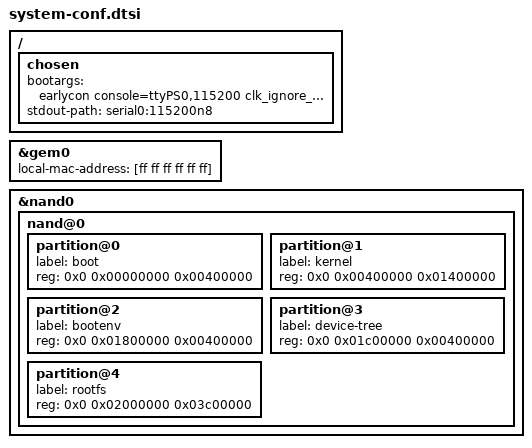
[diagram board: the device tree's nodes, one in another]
/*
 * CAUTION: This file is automatically generated by PetaLinux SDK.
 * DO NOT modify this file
 */


/ {
	chosen {
		bootargs = " earlycon console=ttyPS0,115200 clk_ignore_unused init_fatal_sh=1";
		stdout-path = "serial0:115200n8";
	};
};

&gem0 {
	local-mac-address = [ff ff ff ff ff ff];
};

&nand0 {
	nand@0 {
		partition@0 {
			label = "boot";
			reg = <0x0 0x00000000 0x00400000>;
		};
		partition@1 {
			label = "kernel";
			reg = <0x0 0x00400000 0x01400000>;
		};
		partition@2 {
			label = "bootenv";
			reg = <0x0 0x01800000 0x00400000>;
		};
		partition@3 {
			label = "device-tree";
			reg = <0x0 0x01c00000 0x00400000>;
		};
		partition@4 {
			label = "rootfs";
			reg = <0x0 0x02000000 0x03c00000>;
		};
	};
};

